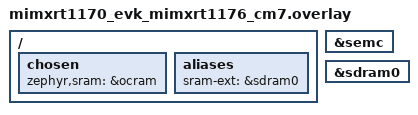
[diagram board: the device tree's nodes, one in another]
/*
 * Copyright 2026 NXP
 *
 * SPDX-License-Identifier: Apache-2.0
 */

/ {
	chosen {
		/*
		 * Keep sample RAM in internal OCRAM so SEMC reset/reconfigure
		 * does not invalidate the active stack/data region.
		 */
		zephyr,sram = &ocram;
	};

	aliases {
		sram-ext = &sdram0;
	};
};

&semc {
	status = "okay";
};

&sdram0 {
	status = "okay";
};
